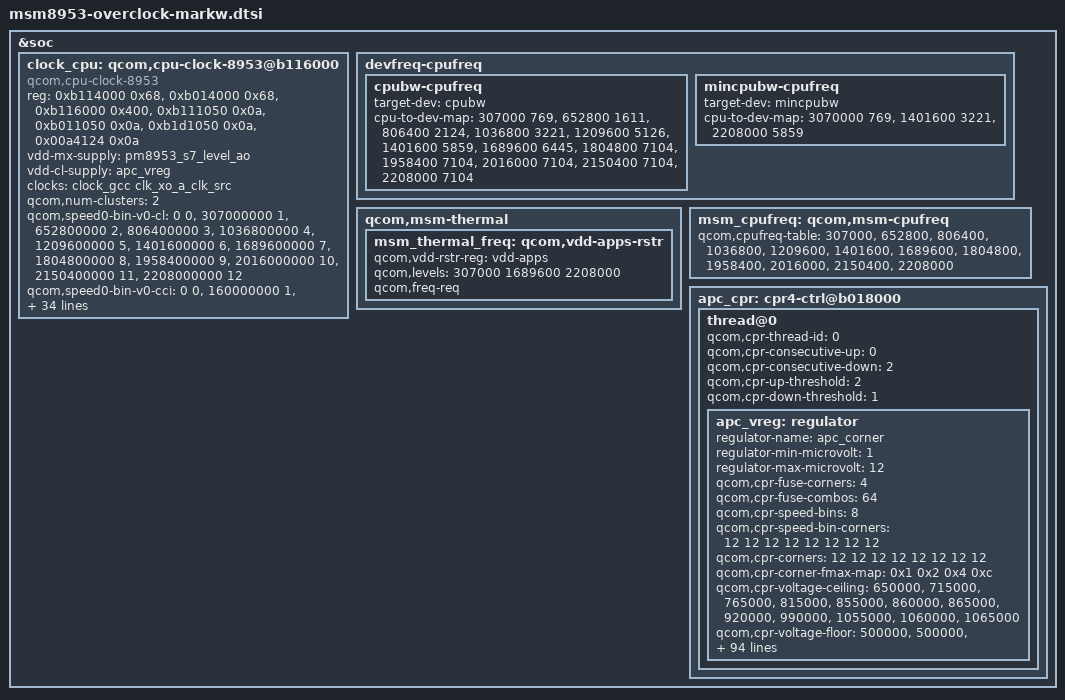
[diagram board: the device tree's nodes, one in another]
/*
 * Copyright (c) 2015-2016, The Linux Foundation. All rights reserved.
 * Copyright (C) 2017 XiaoMi, Inc.
 *
 * This program is free software; you can redistribute it and/or modify
 * it under the terms of the GNU General Public License version 2 and
 * only version 2 as published by the Free Software Foundation.
 *
 * This program is distributed in the hope that it will be useful,
 * but WITHOUT ANY WARRANTY; without even the implied warranty of
 * MERCHANTABILITY or FITNESS FOR A PARTICULAR PURPOSE.  See the
 * GNU General Public License for more details.
 */

/* dts for overckloc markw (for future)*/
/* for сpu in msm8953.dtsi*/
&soc {
	clock_cpu: qcom,cpu-clock-8953@b116000 {
		compatible = "qcom,cpu-clock-8953";
		reg =   <0xb114000  0x68>,
			<0xb014000  0x68>,
			<0xb116000  0x400>,
			<0xb111050  0x0a>,
			<0xb011050  0x0a>,
			<0xb1d1050  0x0a>,
			<0x00a4124  0x0a>;
		reg-names = "rcgwr-c0-base", "rcgwr-c1-base",
			    "c0-pll", "c0-mux", "c1-mux",
			    "cci-mux", "efuse";
		vdd-mx-supply = <&pm8953_s7_level_ao>;
		vdd-cl-supply = <&apc_vreg>;
		clocks = <&clock_gcc clk_xo_a_clk_src>;
		clock-names = "xo_a";
		qcom,num-clusters = <2>;
		qcom,speed0-bin-v0-cl =
			         <0 0>,
			<307000000  1>,
			<652800000  2>,
			<806400000  3>,
			<1036800000 4>,
			<1209600000 5>,
			<1401600000 6>,
			<1689600000 7>,
			<1804800000 8>,
			<1958400000 9>,
			<2016000000 10>,
			<2150400000 11>,
            <2208000000 12>;


		qcom,speed0-bin-v0-cci =
					<0  0>,
			<160000000  1>,
			<261120000  2>,
			<320000000  3>,
			<414720000  4>,
			<483840000  5>,
			<560640000  6>,
			<675840000  7>,
			<721920000  8>,
			<783360000  9>,
			<806400000  10>,
			<860160000  11>,
			<883200000  12>;

		qcom,speed2-bin-v0-cl=
			 	 <0  0>,
			<307000000  1>,
			<652800000  2>,
			<806400000  3>,
			<1036800000  4>,
			<1209600000  5>,
			<1401600000  6>,
			<1689600000  7>,
			<1804800000  8>,
			<1958400000  9>,
			<2016000000  10>,
			<2150400000  11>,
			<2208000000  12>;

		qcom,speed2-bin-v0-cci =
			        <0  0>,
			<160000000  1>,
			<261120000  2>,
			<320000000  3>,
			<414720000  4>,
			<483840000  5>,
			<560640000  6>,
			<675840000  7>,
			<721920000  8>,
			<783360000  9>,
			<806400000  10>,
			<860160000  11>,
			<883200000  12>;
		qcom,speed7-bin-v0-cl =
					<0  0>,
			<307000000  1>,
			<652800000  2>,
			<806400000  3>,
			<1036800000  4>,
			<1209600000  5>,
			<1401600000  6>,
			<1689600000  7>,
			<1804800000  8>,
			<1958400000  9>,
			<2016000000 10>,
			<2150400000 11>,
			<2208000000 12>;
		qcom,speed7-bin-v0-cci =
					<0  0>,
			<160000000  1>,
			<261120000  2>,
			<320000000  3>,
			<414720000  4>,
			<483840000  5>,
			<560640000  6>,
			<675840000  7>,
			<721920000  8>,
			<783360000  9>,
			<806400000  10>,
			<860160000  11>,
			<883200000  12>;
		qcom,speed6-bin-v0-cl =
					<0  0>,
			<307000000  1>,
			<652800000  2>,
			<806400000  3>,
			<1036800000  4>,
			<1209600000  5>,
			<1401600000  6>,
			<1689600000  7>,
			<1804800000  8>,
			<1958400000  9>,
			<2016000000 10>,
			<2150400000 11>,
			<2208000000 12>;
		qcom,speed6-bin-v0-cci =
			    	<0  0>,
			<160000000  1>,
			<261120000  2>,
			<320000000  3>,
			<414720000  4>,
			<483840000  5>,
			<560640000  6>,
			<675840000  7>,
			<721920000  8>,
			<783360000  9>,
			<806400000 10>,
			<860160000 11>,
            <883200000 12>;
    #clock-cells = <1>; 
  }; 
 
  devfreq-cpufreq { 
    cpubw-cpufreq { 
    target-dev = <&cpubw>; 
    cpu-to-dev-map = 
			< 307000  769>,
			< 652800 1611>,
			< 806400 2124>,
			<1036800 3221>,
			<1209600 5126>,
			<1401600 5859>,
			<1689600 6445>,
			<1804800 7104>,
			<1958400 7104>,
			<2016000 7104>,
            <2150400 7104>,
			<2208000 7104>;
			};

		mincpubw-cpufreq {
			target-dev = <&mincpubw>;
			cpu-to-dev-map =
			<3070000 769>,
			<1401600 3221>,
            <2208000 5859>;
			};
		};

	qcom,msm-thermal {
		msm_thermal_freq: qcom,vdd-apps-rstr {
			qcom,vdd-rstr-reg = "vdd-apps";
			qcom,levels = <307000 1689600 2208000>;
			qcom,freq-req;
		};
	};

	msm_cpufreq: qcom,msm-cpufreq {
		qcom,cpufreq-table =
			< 307000>,
			< 652800>,
			< 806400>,
			<1036800>,
			<1209600>,
			<1401600>,
			<1689600>,
			<1804800>,
			<1958400>,
			<2016000>,
			<2150400>,
            <2208000>;
	};

};

/* for cpu in msm8953-regulator.dtsi*/
&soc {
	apc_cpr: cpr4-ctrl@b018000 {
		thread@0 {
			qcom,cpr-thread-id = <0>;
			qcom,cpr-consecutive-up = <0>;
			qcom,cpr-consecutive-down = <2>;
			qcom,cpr-up-threshold = <2>;
			qcom,cpr-down-threshold = <1>;

			apc_vreg: regulator {
				regulator-name = "apc_corner";
				regulator-min-microvolt = <1>;
				regulator-max-microvolt = <12>;

				qcom,cpr-fuse-corners = <4>;
				qcom,cpr-fuse-combos = <64>;
				qcom,cpr-speed-bins = <8>;
				qcom,cpr-speed-bin-corners = <12 12 12 12 12 12 12 12>;
				qcom,cpr-corners = <12 12 12 12 12 12 12 12>;

				qcom,cpr-corner-fmax-map = <0x1 0x2 0x4 0xc>;

				qcom,cpr-voltage-ceiling =
					<650000>,
					<715000>,
					<765000>,
					<815000>,
					<855000>,
					<860000>,
					<865000>,
					<920000>,
					<990000>,
					<1055000>,
					<1060000>,
					<1065000>;

				qcom,cpr-voltage-floor =
					<500000>,
					<500000>,
					<500000>,
					<500000>,
					<500000>,
					<500000>,
					<500000>,
					<500000>,
					<500000>,
					<500000>,
					<500000>,
					<500000>;

				qcom,cpr-floor-to-ceiling-max-range =
					<    0     0     0     0     0     0     0     0     0     0     0     0>,
					<50000 50000 50000 50000 50000 50000 50000 50000 50000 50000 50000 50000>,
					<50000 50000 50000 50000 50000 50000 50000 50000 50000 50000 50000 50000>,
					<50000 50000 50000 50000 50000 50000 50000 50000 50000 50000 50000 50000>,
					<50000 50000 50000 50000 50000 50000 50000 50000 50000 50000 50000 50000>,
					<50000 50000 50000 50000 50000 50000 50000 50000 50000 50000 50000 50000>,
					<50000 50000 50000 50000 50000 50000 50000 50000 50000 50000 50000 50000>,
					<50000 50000 50000 50000 50000 50000 50000 50000 50000 50000 50000 50000>;

				qcom,cpr-misc-fuse-voltage-adjustment =
					<0 0 0 0     0 0>,
					<0 0 0 0     0 0>,
					<0 0 0 0 30000 0>,
					<0 0 0 0     0 0>;

				qcom,mem-acc-voltage = <1 1 1 1 2 2 2 2 2 2 2 2>;

				qcom,corner-frequencies =
					<307000000>,
					<652800000>,
					<806400000>,
					<1036800000>,
					<1209600000>,
					<1401600000>,
					<1689600000>,
					<1804800000>,
					<1958400000>,
					<2016000000>,
					<2150400000>,
					<2208000000>;

				qcom,cpr-open-loop-voltage-fuse-adjustment =
					/* Speed bin 0; CPR rev 0..7 */
					<     0      0      0     0>,
					< 25000      0   5000 40000>,
					< 25000      0   5000 40000>,
					< 25000      0   5000 40000>,
					<     0      0      0     0>,
					<     0      0      0     0>,
					<     0      0      0     0>,
					<     0      0      0     0>,

					/* Speed bin 1; CPR rev 0..7 */
					<     0      0      0     0>,
					<     0      0      0     0>,
					<     0      0      0     0>,
					<     0      0      0     0>,
					<     0      0      0     0>,
					<     0      0      0     0>,
					<     0      0      0     0>,
					<     0      0      0     0>,

					/* Speed bin 2; CPR rev 0..7 */
					<     0      0      0     0>,
					< 25000      0   5000 40000>,
					< 25000      0   5000 40000>,
					< 25000      0   5000 40000>,
					<     0      0      0     0>,
					<     0      0      0     0>,
					<     0      0      0     0>,
					<     0      0      0     0>,

					/* Speed bin 3; CPR rev 0..7 */
					<     0      0      0     0>,
					<     0      0      0     0>,
					<     0      0      0     0>,
					<     0      0      0     0>,
					<     0      0      0     0>,
					<     0      0      0     0>,
					<     0      0      0     0>,
					<     0      0      0     0>,

					/* Speed bin 4; CPR rev 0..7 */
					<     0      0      0     0>,
					<     0      0      0     0>,
					<     0      0      0     0>,
					<     0      0      0     0>,
					<     0      0      0     0>,
					<     0      0      0     0>,
					<     0      0      0     0>,
					<     0      0      0     0>,

					/* Speed bin 5; CPR rev 0..7 */
					<     0      0      0     0>,
					<     0      0      0     0>,
					<     0      0      0     0>,
					<     0      0      0     0>,
					<     0      0      0     0>,
					<     0      0      0     0>,
					<     0      0      0     0>,
					<     0      0      0     0>,

					/* Speed bin 6; CPR rev 0..7 */
					<     0      0      0     0>,
					< 25000      0   5000 40000>,
					< 25000      0   5000 40000>,
					< 25000      0   5000 40000>,
					<     0      0      0     0>,
					<     0      0      0     0>,
					<     0      0      0     0>,
					<     0      0      0     0>,

					/* Speed bin 7; CPR rev 0..7 */
					<     0      0      0     0>,
					< 25000      0   5000 40000>,
					< 25000      0   5000 40000>,
					< 25000      0   5000 40000>,
					<     0      0      0     0>,
					<     0      0      0     0>,
					<     0      0      0     0>,
					<     0      0      0     0>;

				qcom,cpr-closed-loop-voltage-fuse-adjustment =
					/* Speed bin 0; CPR rev 0..7 */
					<      0        0        0      0>,
					<  10000 (-15000)        0  25000>,
					<  10000 (-15000)        0  25000>,
					<(-5000) (-30000) (-15000)  10000>,
					<      0        0        0      0>,
					<      0        0        0      0>,
					<      0        0        0      0>,
					<      0        0        0      0>,

					/* Speed bin 1; CPR rev 0..7 */
					<      0        0        0      0>,
					<      0        0        0      0>,
					<      0        0        0      0>,
					<      0        0        0      0>,
					<      0        0        0      0>,
					<      0        0        0      0>,
					<      0        0        0      0>,
					<      0        0        0      0>,

					/* Speed bin 2; CPR rev 0..7 */
					<      0        0        0      0>,
					<  10000 (-15000)        0  25000>,
					<  10000 (-15000)        0  25000>,
					<(-5000) (-30000) (-15000)  10000>,
					<      0        0        0      0>,
					<      0        0        0      0>,
					<      0        0        0      0>,
					<      0        0        0      0>,

					/* Speed bin 3; CPR rev 0..7 */
					<      0        0        0      0>,
					<      0        0        0      0>,
					<      0        0        0      0>,
					<      0        0        0      0>,
					<      0        0        0      0>,
					<      0        0        0      0>,
					<      0        0        0      0>,
					<      0        0        0      0>,

					/* Speed bin 4; CPR rev 0..7 */
					<      0        0        0      0>,
					<      0        0        0      0>,
					<      0        0        0      0>,
					<      0        0        0      0>,
					<      0        0        0      0>,
					<      0        0        0      0>,
					<      0        0        0      0>,
					<      0        0        0      0>,

					/* Speed bin 5; CPR rev 0..7 */
					<      0        0        0      0>,
					<      0        0        0      0>,
					<      0        0        0      0>,
					<      0        0        0      0>,
					<      0        0        0      0>,
					<      0        0        0      0>,
					<      0        0        0      0>,
					<      0        0        0      0>,

					/* Speed bin 6; CPR rev 0..7 */
					<      0        0        0      0>,
					<  10000 (-15000)        0  25000>,
					<  10000 (-15000)        0  25000>,
					<(-5000) (-30000) (-15000)  10000>,
					<      0        0        0      0>,
					<      0        0        0      0>,
					<      0        0        0      0>,
					<      0        0        0      0>,

					/* Speed bin 7; CPR rev 0..7 */
					<      0        0        0      0>,
					<  10000 (-15000)        0  25000>,
					<  10000 (-15000)        0  25000>,
					<(-5000) (-30000) (-15000)  10000>,
					<      0        0        0      0>,
					<      0        0        0      0>,
					<      0        0        0      0>,
					<      0        0        0      0>;

				qcom,cpr-ro-scaling-factor =
				      <3610 3790    0 2200 2450 2310 2170 2210
				       2330 2210 2470 2340  780 2700 2450 2090>,
				      <3610 3790    0 2200 2450 2310 2170 2210
				       2330 2210 2470 2340  780 2700 2450 2090>,
				      <3610 3790    0 2200 2450 2310 2170 2210
				       2330 2210 2470 2340  780 2700 2450 2090>,
				      <3610 3790    0 2200 2450 2310 2170 2210
				       2330 2210 2470 2340  780 2700 2450 2090>;

				qcom,allow-voltage-interpolation;
				qcom,allow-quotient-interpolation;
				qcom,cpr-scaled-open-loop-voltage-as-ceiling;

				qcom,corner-allow-temp-adjustment =
					<0 0 0 0 0 0 0 0 0 0 0 0>,
					<0 0 0 0 0 0 0 0 0 0 0 0>,
					<0 0 0 0 0 0 0 0 0 0 0 0>,
					<1 1 1 1 1 0 0 0 0 0 0 0>,
					<1 1 1 1 1 0 0 0 0 0 0 0>,
					<1 1 1 1 1 0 0 0 0 0 0 0>,
					<1 1 1 1 1 0 0 0 0 0 0 0>,
					<1 1 1 1 1 0 0 0 0 0 0 0>;

				qcom,cpr-corner1-temp-core-voltage-adjustment =
					<(0) (-5000) (-15000) (-20000)>;

				qcom,cpr-corner2-temp-core-voltage-adjustment =
					<(0) (-5000) (-15000) (-15000)>;

				qcom,cpr-corner3-temp-core-voltage-adjustment =
					<(0) (-5000) (-15000) (-10000)>;

				qcom,cpr-corner4-temp-core-voltage-adjustment =
					<(0) (-5000) (-15000)      (0)>;

				qcom,cpr-corner5-temp-core-voltage-adjustment =
					<(0) (-5000) (-15000)      (0)>;

				qcom,cpr-aging-max-voltage-adjustment = <15000>;
				qcom,cpr-aging-ref-corner = <6>; /* Turbo */
				qcom,cpr-aging-ro-scaling-factor = <2800>;
				qcom,allow-aging-voltage-adjustment = <0 0 0 1 1 1 1 1>;
			};
		};
	};
};
